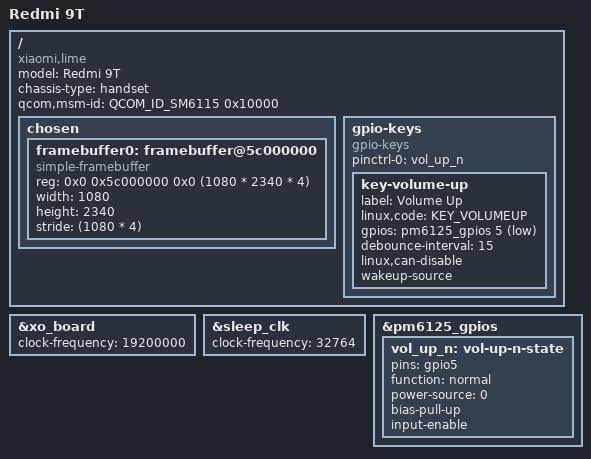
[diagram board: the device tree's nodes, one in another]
// SPDX-License-Identifier: (GPL-2.0+ OR BSD-3-Clause)
/*
 * Copyright (c) 2024, Abhisit Sangjan <abhisit.sangjan@gmail.com>
 */

/dts-v1/;

#include "sm6115.dtsi"
#include "pm6125.dtsi"
#include <dt-bindings/arm/qcom,ids.h>

/ {
	model = "Redmi 9T";
	compatible = "xiaomi,lime", "qcom,sm6115";
	chassis-type = "handset";

	qcom,msm-id = <QCOM_ID_SM6115 0x10000>;

	chosen {
		#address-cells = <2>;
		#size-cells = <2>;
		ranges;

		framebuffer0: framebuffer@5c000000 {
			compatible = "simple-framebuffer";
			reg = <0x0 0x5c000000 0x0 (1080 * 2340 * 4)>;
			width = <1080>;
			height = <2340>;
			stride = <(1080 * 4)>;
		};
	};

	gpio-keys {
		compatible = "gpio-keys";

		pinctrl-0 = <&vol_up_n>;
		pinctrl-names = "default";

		key-volume-up {
			label = "Volume Up";
			linux,code = <KEY_VOLUMEUP>;
			gpios = <&pm6125_gpios 5 GPIO_ACTIVE_LOW>;
			debounce-interval = <15>;
			linux,can-disable;
			wakeup-source;
		};
	};
};

&xo_board {
	clock-frequency = <19200000>;
};

&sleep_clk {
	clock-frequency = <32764>;
};

&pm6125_gpios {
	vol_up_n: vol-up-n-state {
		pins = "gpio5";
		function = "normal";
		power-source = <0>;
		bias-pull-up;
		input-enable;
	};
};
